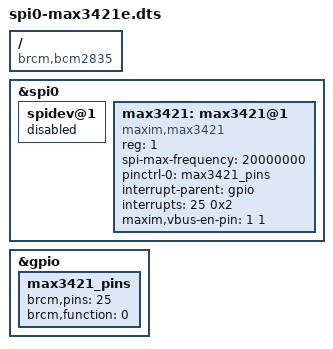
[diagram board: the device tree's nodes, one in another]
/dts-v1/;
/plugin/;

/ {
    compatible = "brcm,bcm2835";
    /* Disable spidev for spi0.1 - release resource */
    fragment@0 {
        target = <&spi0>;
        __overlay__ {
            status = "okay";
            spidev@1{
                status = "disabled";
            };
        };
    };

    /* Set pins used (IRQ) */
    fragment@1 {
        target = <&gpio>;
        __overlay__ {
            max3421_pins: max3421_pins {
                brcm,pins = <25>;		//GPIO25
                brcm,function = <0>;	//Input
            };
        };
    };

    /* Create the MAX3421 node */
    fragment@2 {
        target = <&spi0>;
        __overlay__ {
            //avoid dtc warning 
            #address-cells = <1>;
            #size-cells = <0>;
            max3421: max3421@1 {
                reg = <1>;	//CS 1
                spi-max-frequency = <20000000>;
                compatible = "maxim,max3421";
                pinctrl-names = "default";
                pinctrl-0 = <&max3421_pins>;
                interrupt-parent = <&gpio>;
                interrupts = <25 0x2>; 		//GPIO25, high-to-low
                maxim,vbus-en-pin = <1 1>;	//MAX GPOUT1, active high
            };
        };
    };

    __overrides__ {
        spimaxfrequency = <&max3421>,"spi-max-frequency:0";
        interrupt = <&max3421_pins>,"brcm,pins:0",<&max3421>,"interrupts:0";
        vbus-en-pin = <&max3421>,"maxim,vbus-en-pin:0";
        vbus-en-level = <&max3421>,"maxim,vbus-en-pin:4";
    };
};
